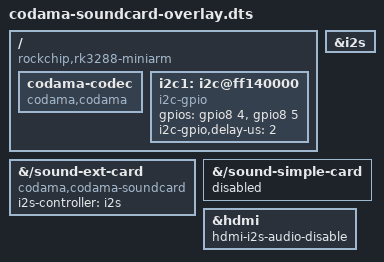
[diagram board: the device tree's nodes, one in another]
/dts-v1/;
/plugin/;

/ {
	compatible = "rockchip,rk3288-miniarm", "rockchip,rk3288";

	fragment@0 {
		target = <&i2s>;
		__overlay__ {
			status = "okay";
		};
	};

	fragment@1 {
		target-path = "/";
		__overlay__ {
			codama-codec {
				#sound-dai-cells = <0>;
				compatible = "codama,codama";
				status = "okay";
			};

			i2c1: i2c@ff140000 {
				compatible = "i2c-gpio";

				gpios = <&gpio8 4 0
					 &gpio8 5 0
				>;
				i2c-gpio,delay-us = <2>;

				status = "ok";
			};
		};
	};

	fragment@2 {
		target-path = "/sound-ext-card";
		__overlay__ {
			compatible = "codama,codama-soundcard";
			i2s-controller = <&i2s>;
			status = "okay";
		};
	};

	fragment@3 {
                target-path ="/sound-simple-card";
                __overlay__ {
                        status = "disabled";
                };
        };

	fragment@4 {
		target = <&hdmi>;
		__overlay__ {
			hdmi-i2s-audio-disable;
		};
	};
};
